# DDR32SS0_CTLPHY_WRAP_CTL_CFG_CTLCFG register map
Vendor: Texas Instruments
Registers are 32-bit, read-write, reset 0x0 unless marked. A register's access mark holds for its fields unless they carry their own. Offsets are as the file gives them; [hi:lo] are bit positions; {n}, {i} and the like mark numbered series.

## DDR32SS0_CTLPHY_WRAP_CTL_CFG_CTLCFG (part 9 of 11)
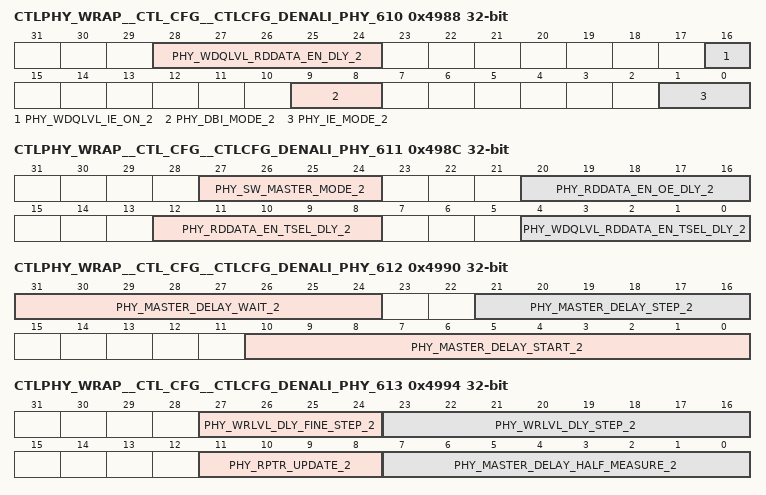
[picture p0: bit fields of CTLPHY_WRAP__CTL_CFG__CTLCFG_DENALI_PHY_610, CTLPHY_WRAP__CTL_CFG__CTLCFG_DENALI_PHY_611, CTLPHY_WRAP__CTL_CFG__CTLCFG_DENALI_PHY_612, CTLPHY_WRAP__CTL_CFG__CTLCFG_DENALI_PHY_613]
0x4988 CTLPHY_WRAP__CTL_CFG__CTLCFG_DENALI_PHY_610
  [28:24] PHY_WDQLVL_RDDATA_EN_DLY_2 — For WR DQ training, the number of cycles that the dfi_rddata_en signal is early for slice 2.
  [16] PHY_WDQLVL_IE_ON_2 — IE control, 1 meams IE is always on during WR DQ training for slice 2.
  [9:8] PHY_DBI_MODE_2 — DBI mode for slice 2. Bit [0] enables return of DBI read data.
  [1:0] PHY_IE_MODE_2 — Input enable mode bits for slice 2. Bit [0] enables the mode where the input enables are always on; set to 1 to enable. Bit [1] disables the input enable on the DM signal; set to 1 to disable.
0x498C CTLPHY_WRAP__CTL_CFG__CTLCFG_DENALI_PHY_611
  [27:24] PHY_SW_MASTER_MODE_2 — Controller delay line override settings for slice 2. Bit [0] enables software half clock mode. Bit [1] is the software half clock mode value. Bit [2] enables software bypass mode. Bit [3] is the software bypass mode value.
  [20:16] PHY_RDDATA_EN_OE_DLY_2 — Number of cycles that the dfi_rddata_en signal is earlier than necessary for LP4 OE extension generation for slice 2.
  [12:8] PHY_RDDATA_EN_TSEL_DLY_2 — Number of cycles that the dfi_rddata_en signal is earlier than necessary for TSEL enable generation for slice 2.
  [4:0] PHY_WDQLVL_RDDATA_EN_TSEL_DLY_2 — For WR DQ training, the number of cycles that the dfi_rddata_en signal is earlier than necessary for TSEL enable generation for slice 2.
0x4990 CTLPHY_WRAP__CTL_CFG__CTLCFG_DENALI_PHY_612
  [31:24] PHY_MASTER_DELAY_WAIT_2 — Wait cycles for controller delay line locking algorithm for slice 2. Bits [3:0] are the cycle wait count after a calibration clock setting change. Bits [7:4] are the cycle wait count after a controller delay setting change.
  [21:16] PHY_MASTER_DELAY_STEP_2 — Incremental step size for controller delay line locking algorithm for slice 2.
  [10:0] PHY_MASTER_DELAY_START_2 — Start value for controller delay line locking algorithm for slice 2.
0x4994 CTLPHY_WRAP__CTL_CFG__CTLCFG_DENALI_PHY_613
  [27:24] PHY_WRLVL_DLY_FINE_STEP_2 — DQS target delay fine step size during write leveling for slice 2.
  [23:16] PHY_WRLVL_DLY_STEP_2 — DQS target delay step size during write leveling for slice 2.
  [11:8] PHY_RPTR_UPDATE_2 — Offset in cycles from the dfi_rddata_en signal to release data from the entry FIFO for slice 2.
  [7:0] PHY_MASTER_DELAY_HALF_MEASURE_2 — Defines the number of delay line elements to be considered in determing whether to lock to a half clock cycle in the data slice controller for slice 2.
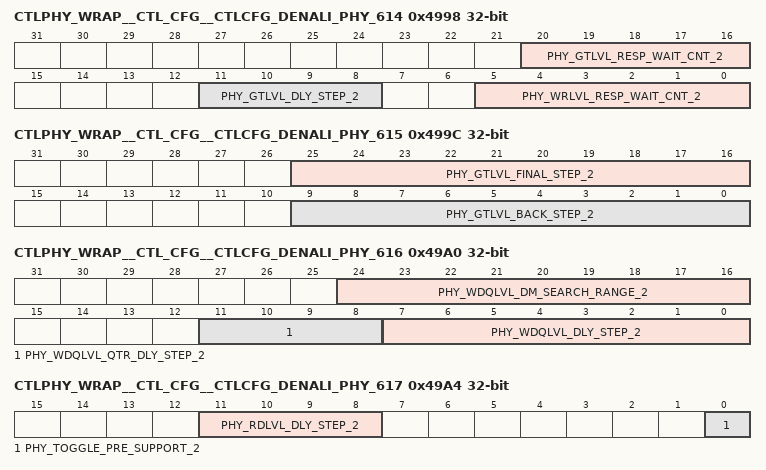
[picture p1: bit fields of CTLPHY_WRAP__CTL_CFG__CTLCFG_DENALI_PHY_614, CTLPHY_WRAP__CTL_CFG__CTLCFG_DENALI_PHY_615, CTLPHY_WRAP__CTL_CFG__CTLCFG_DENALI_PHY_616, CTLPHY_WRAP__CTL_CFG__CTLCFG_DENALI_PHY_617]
0x4998 CTLPHY_WRAP__CTL_CFG__CTLCFG_DENALI_PHY_614
  [20:16] PHY_GTLVL_RESP_WAIT_CNT_2 — Number of cycles + 4 to wait between dfi_rddata_en and the sampling of the DQS during gate training for slice 2. The valid range is 0x0 to 0xB.
  [11:8] PHY_GTLVL_DLY_STEP_2 — DQS target delay step size during gate training for slice 2.
  [5:0] PHY_WRLVL_RESP_WAIT_CNT_2 — Number of cycles to wait between dfi_wrlvl_strobe and the sampling of the DQs during write leveling for slice 2.
0x499C CTLPHY_WRAP__CTL_CFG__CTLCFG_DENALI_PHY_615
  [25:16] PHY_GTLVL_FINAL_STEP_2 — Final backup step delay used in gate training algorithm for slice 2.
  [9:0] PHY_GTLVL_BACK_STEP_2 — Interim backup step delay used in gate training algorithm for slice 2.
0x49A0 CTLPHY_WRAP__CTL_CFG__CTLCFG_DENALI_PHY_616
  [24:16] PHY_WDQLVL_DM_SEARCH_RANGE_2 — The dm target delay search range for non-lpddr4 DM training for slice 2.
  [11:8] PHY_WDQLVL_QTR_DLY_STEP_2 — Defines the step granularity for the logic to use once an edge is found for slice 2. When this occurs, the logic jumps back to the previous invalid value and uses this step size to determine a more accurate delay value.
  [7:0] PHY_WDQLVL_DLY_STEP_2 — DQ target delay step size during write data leveling for slice 2.
0x49A4 CTLPHY_WRAP__CTL_CFG__CTLCFG_DENALI_PHY_617
  [11:8] PHY_RDLVL_DLY_STEP_2 — DQS target delay step size during read leveling for slice 2.
  [0] PHY_TOGGLE_PRE_SUPPORT_2 — Support the toggle read preamble for LPDDR4 for slice 2.
0x49A8 CTLPHY_WRAP__CTL_CFG__CTLCFG_DENALI_PHY_618
  [9:0] PHY_RDLVL_MAX_EDGE_2 — The maximun rdlvl target delay search window for read eye training for slice 2.
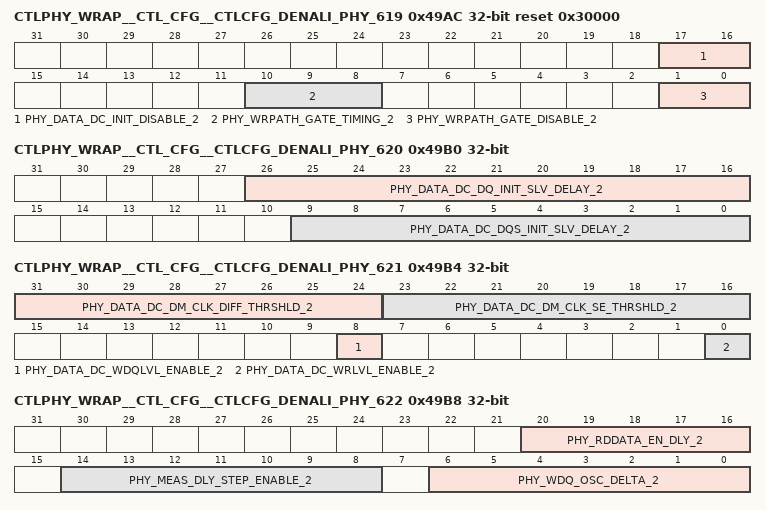
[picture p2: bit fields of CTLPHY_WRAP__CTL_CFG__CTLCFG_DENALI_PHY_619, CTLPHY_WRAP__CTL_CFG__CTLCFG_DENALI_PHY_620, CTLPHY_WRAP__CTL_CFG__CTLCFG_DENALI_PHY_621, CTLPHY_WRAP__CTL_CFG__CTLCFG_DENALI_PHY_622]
0x49AC CTLPHY_WRAP__CTL_CFG__CTLCFG_DENALI_PHY_619 reset 0x30000
  [17:16] PHY_DATA_DC_INIT_DISABLE_2 — Disable duty cycle adjust at initialization for slice 2.
  [10:8] PHY_WRPATH_GATE_TIMING_2 — Write path clock gating timing for slice 2. it means additional clock number to write path clock gate
  [1:0] PHY_WRPATH_GATE_DISABLE_2 — Write path clock gating disable for slice 2. [0]: disable pull in wrdata_en; [1]: disable write path clock gating, clock always on
0x49B0 CTLPHY_WRAP__CTL_CFG__CTLCFG_DENALI_PHY_620
  [26:16] PHY_DATA_DC_DQ_INIT_SLV_DELAY_2 — Initial value of write DQ target delay for slice 2.
  [9:0] PHY_DATA_DC_DQS_INIT_SLV_DELAY_2 — Initial value of write DQS target delay for slice 2.
0x49B4 CTLPHY_WRAP__CTL_CFG__CTLCFG_DENALI_PHY_621
  [31:24] PHY_DATA_DC_DM_CLK_DIFF_THRSHLD_2 — Clock measurement cell threshold offset for differential signals for slice 2.
  [23:16] PHY_DATA_DC_DM_CLK_SE_THRSHLD_2 — Clock measurement cell threshold offset for single ended signals for slice 2.
  [8] PHY_DATA_DC_WDQLVL_ENABLE_2 — Enable duty cycle adjust during write DQ training for slice 2.
  [0] PHY_DATA_DC_WRLVL_ENABLE_2 — Enable duty cycle adjust during write leveling for slice 2.
0x49B8 CTLPHY_WRAP__CTL_CFG__CTLCFG_DENALI_PHY_622
  [20:16] PHY_RDDATA_EN_DLY_2 — Number of cycles that the dfi_rddata_en signal is early for slice 2.
  [14:8] PHY_MEAS_DLY_STEP_ENABLE_2 — Data slice training step definition using phy_meas_dly_step_value for slice 2.
  [6:0] PHY_WDQ_OSC_DELTA_2 — Target delay offset that applies to a 1 bit change of dfi_wdq_osc_code for slice 2.
0x49BC CTLPHY_WRAP__CTL_CFG__CTLCFG_DENALI_PHY_623
  [31:0] PHY_DQ_DM_SWIZZLE0_2 — DQ/DM bit swizzling 0 for slice 2. Bits [3:0] inform the PHY which bit in {DM,DQ]} map to DQ0, Bits [7:4] inform the PHY which bit in {DM,DQ} map to DQ1, etc.
0x49C0 CTLPHY_WRAP__CTL_CFG__CTLCFG_DENALI_PHY_624
  [3:0] PHY_DQ_DM_SWIZZLE1_2 — DQ/DM bit swizzling 1 for slice 2. Bits [3:0] inform the PHY which bit in {DM,DQ]} map to DM.
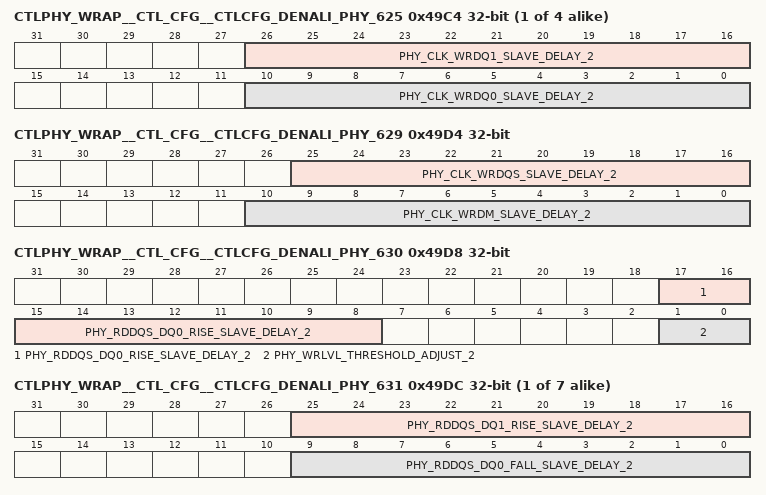
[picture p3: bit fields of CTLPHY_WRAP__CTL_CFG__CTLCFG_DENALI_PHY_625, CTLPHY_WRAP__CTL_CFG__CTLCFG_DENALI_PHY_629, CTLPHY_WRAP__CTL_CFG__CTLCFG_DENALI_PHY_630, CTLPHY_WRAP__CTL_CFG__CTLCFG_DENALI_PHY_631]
{0x4000+4i} CTLPHY_WRAP__CTL_CFG__CTLCFG_DENALI_PHY_{i} (i=625..628)
  [26:16] PHY_CLK_WRDQ{2i-1249}_SLAVE_DELAY_2 — Write clock target delay setting for DQ{2i-1249} for slice 2.
  [10:0] PHY_CLK_WRDQ{2i-1250}_SLAVE_DELAY_2 — Write clock target delay setting for DQ{2i-1250} for slice 2.
0x49D4 CTLPHY_WRAP__CTL_CFG__CTLCFG_DENALI_PHY_629
  [25:16] PHY_CLK_WRDQS_SLAVE_DELAY_2 — Write clock target delay setting for DQS for slice 2.
  [10:0] PHY_CLK_WRDM_SLAVE_DELAY_2 — Write clock target delay setting for DM for slice 2.
0x49D8 CTLPHY_WRAP__CTL_CFG__CTLCFG_DENALI_PHY_630
  [17:8] PHY_RDDQS_DQ0_RISE_SLAVE_DELAY_2 — Rising edge read DQS target delay setting for DQ0 for slice 2.
  [1:0] PHY_WRLVL_THRESHOLD_ADJUST_2 — Write level threshold adjust value based on those thresholds for DQS for slice 2.
{0x4000+4i} CTLPHY_WRAP__CTL_CFG__CTLCFG_DENALI_PHY_{i} (i=631..637)
  [25:16] PHY_RDDQS_DQ{i-630}_RISE_SLAVE_DELAY_2 — Rising edge read DQS target delay setting for DQ{i-630} for slice 2.
  [9:0] PHY_RDDQS_DQ{i-631}_FALL_SLAVE_DELAY_2 — Falling edge read DQS target delay setting for DQ{i-631} for slice 2.
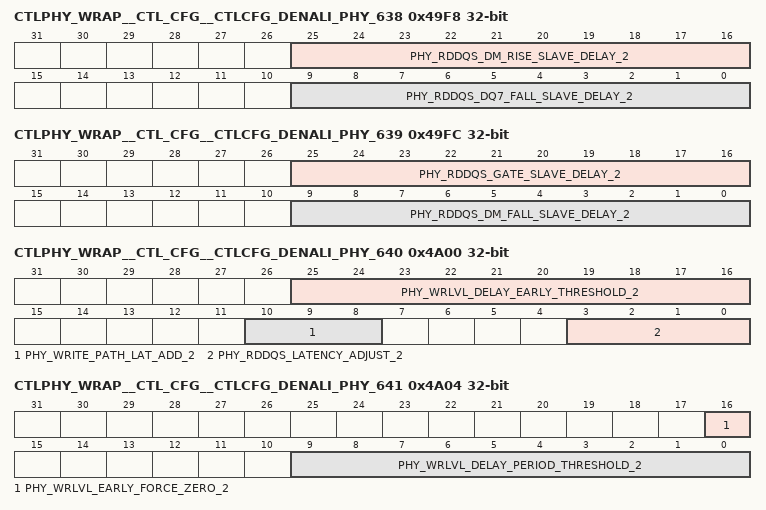
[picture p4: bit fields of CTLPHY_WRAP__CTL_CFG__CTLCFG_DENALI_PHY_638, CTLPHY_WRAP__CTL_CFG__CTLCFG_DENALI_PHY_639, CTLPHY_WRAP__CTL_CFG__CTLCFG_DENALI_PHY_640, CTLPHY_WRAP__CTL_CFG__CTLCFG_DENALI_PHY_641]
0x49F8 CTLPHY_WRAP__CTL_CFG__CTLCFG_DENALI_PHY_638
  [25:16] PHY_RDDQS_DM_RISE_SLAVE_DELAY_2 — Rising edge read DQS target delay setting for DM for slice 2.
  [9:0] PHY_RDDQS_DQ7_FALL_SLAVE_DELAY_2 — Falling edge read DQS target delay setting for DQ7 for slice 2.
0x49FC CTLPHY_WRAP__CTL_CFG__CTLCFG_DENALI_PHY_639
  [25:16] PHY_RDDQS_GATE_SLAVE_DELAY_2 — Read DQS target delay setting for slice 2.
  [9:0] PHY_RDDQS_DM_FALL_SLAVE_DELAY_2 — Falling edge read DQS target delay setting for DM for slice 2.
0x4A00 CTLPHY_WRAP__CTL_CFG__CTLCFG_DENALI_PHY_640
  [25:16] PHY_WRLVL_DELAY_EARLY_THRESHOLD_2 — Write level delay threshold above which will be considered in previous cycle for slice 2.
  [10:8] PHY_WRITE_PATH_LAT_ADD_2 — Number of cycles to delay the incoming dfi_wrdata_en/dfi_wrdata signals for slice 2.
  [3:0] PHY_RDDQS_LATENCY_ADJUST_2 — Number of cycles to delay the incoming dfi_rddata_en for read DQS gate generation for slice 2.
0x4A04 CTLPHY_WRAP__CTL_CFG__CTLCFG_DENALI_PHY_641
  [16] PHY_WRLVL_EARLY_FORCE_ZERO_2 — Force the final write level delay value [that meets the early threshold] to 0 for slice 2.
  [9:0] PHY_WRLVL_DELAY_PERIOD_THRESHOLD_2 — Write level delay threshold below which will add a cycle of write path latency for slice 2.
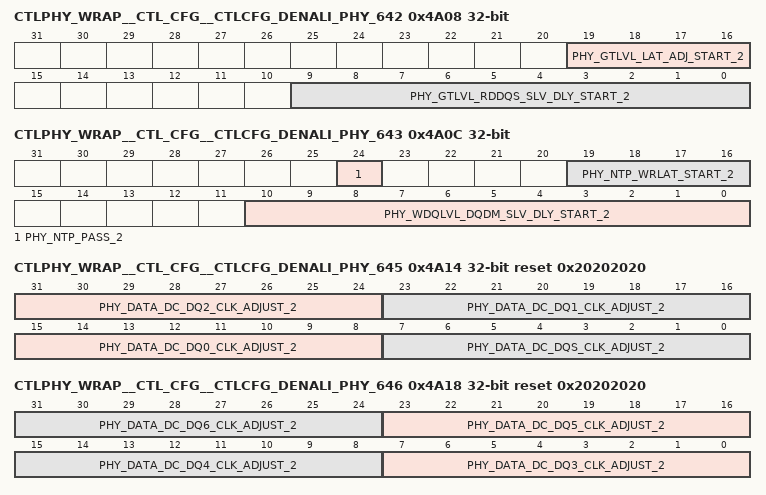
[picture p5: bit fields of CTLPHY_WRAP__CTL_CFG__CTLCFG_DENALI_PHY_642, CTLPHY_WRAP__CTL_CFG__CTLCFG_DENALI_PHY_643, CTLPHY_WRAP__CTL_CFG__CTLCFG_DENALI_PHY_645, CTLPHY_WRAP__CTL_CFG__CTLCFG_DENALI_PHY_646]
0x4A08 CTLPHY_WRAP__CTL_CFG__CTLCFG_DENALI_PHY_642
  [19:16] PHY_GTLVL_LAT_ADJ_START_2 — Initial read DQS gate cycle delay from dfi_rddata_en during gate training for slice 2.
  [9:0] PHY_GTLVL_RDDQS_SLV_DLY_START_2 — Initial read DQS gate target delay setting during gate training for slice 2.
0x4A0C CTLPHY_WRAP__CTL_CFG__CTLCFG_DENALI_PHY_643
  [24] PHY_NTP_PASS_2 — Indicates if No-topology training found a passing result for slice 2.
  [19:16] PHY_NTP_WRLAT_START_2 — Initial value for phy_write_path_lat_add for No-topology training and early threshold for slice 2.
  [10:0] PHY_WDQLVL_DQDM_SLV_DLY_START_2 — Initial DQ/DM target delay setting during write data leveling for slice 2.
0x4A10 CTLPHY_WRAP__CTL_CFG__CTLCFG_DENALI_PHY_644
  [9:0] PHY_RDLVL_RDDQS_DQ_SLV_DLY_START_2 — Read leveling starting value for the DQS/DQ target delay settings for slice 2.
0x4A14 CTLPHY_WRAP__CTL_CFG__CTLCFG_DENALI_PHY_645 reset 0x20202020
  [31:24] PHY_DATA_DC_DQ2_CLK_ADJUST_2 — Adjust value of Duty Cycle Adjuster for slice 2.
  [23:16] PHY_DATA_DC_DQ1_CLK_ADJUST_2 — Adjust value of Duty Cycle Adjuster for slice 2.
  [15:8] PHY_DATA_DC_DQ0_CLK_ADJUST_2 — Adjust value of Duty Cycle Adjuster for slice 2.
  [7:0] PHY_DATA_DC_DQS_CLK_ADJUST_2 — Adjust value of Duty Cycle Adjuster for slice 2.
0x4A18 CTLPHY_WRAP__CTL_CFG__CTLCFG_DENALI_PHY_646 reset 0x20202020
  [8n-17:8n-24] PHY_DATA_DC_DQ{n}_CLK_ADJUST_2 (n=3..6) — Adjust value of Duty Cycle Adjuster for slice 2.
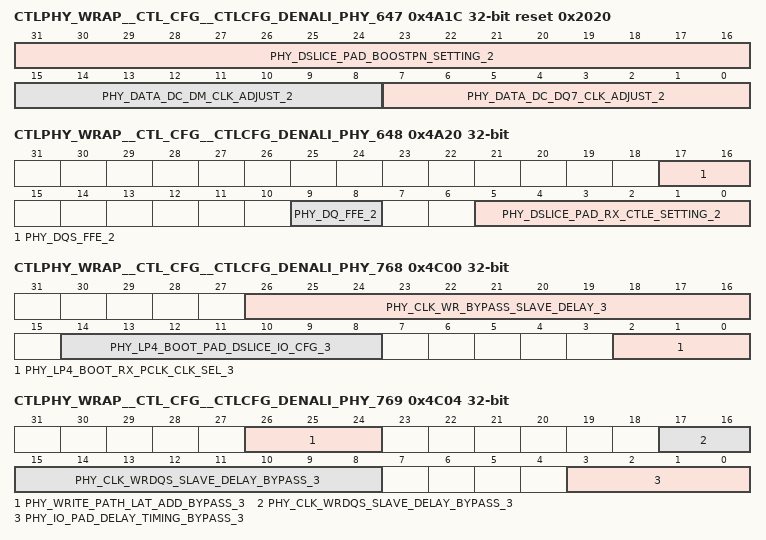
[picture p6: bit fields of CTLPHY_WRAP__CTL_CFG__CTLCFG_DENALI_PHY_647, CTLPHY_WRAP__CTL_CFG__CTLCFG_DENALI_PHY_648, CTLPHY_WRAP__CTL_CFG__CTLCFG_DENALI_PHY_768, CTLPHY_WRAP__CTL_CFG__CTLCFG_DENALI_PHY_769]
0x4A1C CTLPHY_WRAP__CTL_CFG__CTLCFG_DENALI_PHY_647 reset 0x2020
  [31:16] PHY_DSLICE_PAD_BOOSTPN_SETTING_2 — Setting for boost P/N of pad for slice 2.
  [15:8] PHY_DATA_DC_DM_CLK_ADJUST_2 — Adjust value of Duty Cycle Adjuster for slice 2.
  [7:0] PHY_DATA_DC_DQ7_CLK_ADJUST_2 — Adjust value of Duty Cycle Adjuster for slice 2.
0x4A20 CTLPHY_WRAP__CTL_CFG__CTLCFG_DENALI_PHY_648
  [17:16] PHY_DQS_FFE_2 — TX_FFE setting for DQS pad for slice 2.
  [9:8] PHY_DQ_FFE_2 — TX_FFE setting for DQ/DM pad for slice 2.
  [5:0] PHY_DSLICE_PAD_RX_CTLE_SETTING_2 — Setting for RX ctle P/N of pad for slice 2.
0x4C00 CTLPHY_WRAP__CTL_CFG__CTLCFG_DENALI_PHY_768
  [26:16] PHY_CLK_WR_BYPASS_SLAVE_DELAY_3 — Write data clock bypass mode target delay setting for slice 3.
  [14:8] PHY_LP4_BOOT_PAD_DSLICE_IO_CFG_3 — Controls PCLK/PARK pin for pad for slice 3 with boot frequency.
  [2:0] PHY_LP4_BOOT_RX_PCLK_CLK_SEL_3 — RX_PCLK boot clock frequency selection for slice 3.
0x4C04 CTLPHY_WRAP__CTL_CFG__CTLCFG_DENALI_PHY_769
  [26:24] PHY_WRITE_PATH_LAT_ADD_BYPASS_3 — Number of cycles on bypass mode to delay the incoming dfi_wrdata_en/dfi_wrdata signals for slice 3.
  [17:8] PHY_CLK_WRDQS_SLAVE_DELAY_BYPASS_3 — Write DQS bypass mode target delay setting for slice 3.
  [3:0] PHY_IO_PAD_DELAY_TIMING_BYPASS_3 — Feedback pad's OPAD and IPAD delay timing on bypass mode for slice 3.
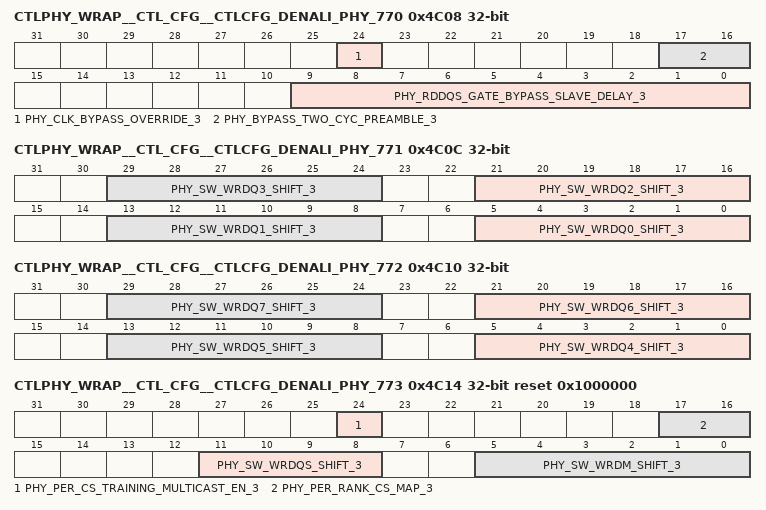
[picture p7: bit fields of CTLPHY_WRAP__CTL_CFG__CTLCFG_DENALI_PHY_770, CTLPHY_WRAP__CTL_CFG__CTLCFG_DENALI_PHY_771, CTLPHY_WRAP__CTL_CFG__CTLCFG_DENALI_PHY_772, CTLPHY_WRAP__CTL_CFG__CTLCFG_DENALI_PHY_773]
0x4C08 CTLPHY_WRAP__CTL_CFG__CTLCFG_DENALI_PHY_770
  [24] PHY_CLK_BYPASS_OVERRIDE_3 — Bypass mode override setting for slice 3.
  [17:16] PHY_BYPASS_TWO_CYC_PREAMBLE_3 — Two_cycle_preamble for bypass mode for slice 3.
  [9:0] PHY_RDDQS_GATE_BYPASS_SLAVE_DELAY_3 — Read DQS bypass mode target delay setting for slice 3.
0x4C0C CTLPHY_WRAP__CTL_CFG__CTLCFG_DENALI_PHY_771
  [8n+5:8n] PHY_SW_WRDQ{n}_SHIFT_3 (n=0..3) — Manual override of automatic half_cycle_shift/cycle_shift for write DQ{n} for slice 3. Bit [0] enables override of half_cycle_shift. Bit [1] is the half_cycle_shift value. Bit [2] enables override of cycle shift. Bits [4:3] are the cycle_shift value.
0x4C10 CTLPHY_WRAP__CTL_CFG__CTLCFG_DENALI_PHY_772
  [8n-27:8n-32] PHY_SW_WRDQ{n}_SHIFT_3 (n=4..7) — Manual override of automatic half_cycle_shift/cycle_shift for write DQ{n} for slice 3. Bit [0] enables override of half_cycle_shift. Bit [1] is the half_cycle_shift value. Bit [2] enables override of cycle shift. Bits [4:3] are the cycle_shift value.
0x4C14 CTLPHY_WRAP__CTL_CFG__CTLCFG_DENALI_PHY_773 reset 0x1000000
  [24] PHY_PER_CS_TRAINING_MULTICAST_EN_3 — When set, a register write will update parameters for all ranks at the same time in slice 3. Set to 1 to enable.
  [17:16] PHY_PER_RANK_CS_MAP_3 — Per-rank CS map for slice 3. Setting a bit uses that CS for the rank, bit [0] uses CS0, bit [1] uses CS1, etc.
  [11:8] PHY_SW_WRDQS_SHIFT_3 — Manual override of automatic half_cycle_shift/cycle_shift for write DQS for slice 3. Bit [0] enables override of half_cycle_shift. Bit [1] is the half_cycle_shift value. Bit [2] enables override of cycle shift. Bit [3] is the cycle_shift value.
  [5:0] PHY_SW_WRDM_SHIFT_3 — Manual override of automatic half_cycle_shift/cycle_shift for write DM for slice 3. Bit [0] enables override of half_cycle_shift. Bit [1] is the half_cycle_shift value. Bit [2] enables override of cycle shift. Bits [4:3] are the cycle_shift value.
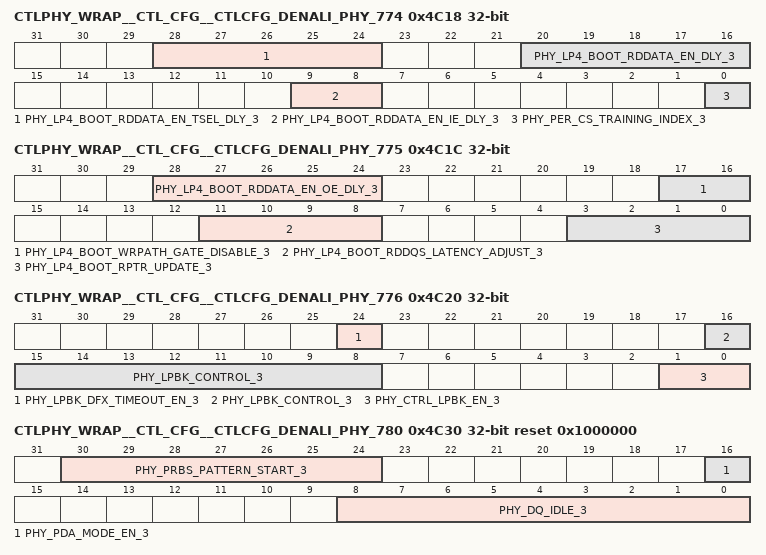
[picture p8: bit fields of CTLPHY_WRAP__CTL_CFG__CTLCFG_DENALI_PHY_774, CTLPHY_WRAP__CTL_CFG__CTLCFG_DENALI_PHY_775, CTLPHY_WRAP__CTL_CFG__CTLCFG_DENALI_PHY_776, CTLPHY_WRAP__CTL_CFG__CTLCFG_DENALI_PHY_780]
0x4C18 CTLPHY_WRAP__CTL_CFG__CTLCFG_DENALI_PHY_774
  [28:24] PHY_LP4_BOOT_RDDATA_EN_TSEL_DLY_3 — For LPDDR4 boot frequency, the number of cycles that the dfi_rddata_en signal is earlier than necessary for TSEL enable generation for slice 3.
  [20:16] PHY_LP4_BOOT_RDDATA_EN_DLY_3 — For LPDDR4 boot frequency, the number of cycles that the dfi_rddata_en signal is early for slice 3.
  [9:8] PHY_LP4_BOOT_RDDATA_EN_IE_DLY_3 — For LPDDR4 boot frequency, the number of cycles that the dfi_rddata_en signal is earlier than necessary for input enable generation for slice 3.
  [0] PHY_PER_CS_TRAINING_INDEX_3 — For per-rank training, indicates which rank's paramters are read/written for slice 3.
0x4C1C CTLPHY_WRAP__CTL_CFG__CTLCFG_DENALI_PHY_775
  [28:24] PHY_LP4_BOOT_RDDATA_EN_OE_DLY_3 — For LPDDR4 boot frequency, the number of cycles that the dfi_rddata_en signal is earlier than necessary for extended OE generation for slice 3.
  [17:16] PHY_LP4_BOOT_WRPATH_GATE_DISABLE_3 — For LPDDR4 boot frequency, write path clock gating disable for slice 3. Bit [0]: disable pull in wrdata_en; Bit [1]: disable write path clock gating, clock always on
  [11:8] PHY_LP4_BOOT_RDDQS_LATENCY_ADJUST_3 — For LPDDR4 boot frequency, the number of cycles to delay the incoming dfi_rddata_en for read DQS gate generation for slice 3.
  [3:0] PHY_LP4_BOOT_RPTR_UPDATE_3 — For LPDDR4 boot frequency, the offset in cycles from the dfi_rddata_en signal to releasing data from the entry FIFO for slice 3.
0x4C20 CTLPHY_WRAP__CTL_CFG__CTLCFG_DENALI_PHY_776
  [24] PHY_LPBK_DFX_TIMEOUT_EN_3 — Loopback read only test timeout mechanism enable for slice 3.
  [16:8] PHY_LPBK_CONTROL_3 — Loopback control bits for slice 3.
  [1:0] PHY_CTRL_LPBK_EN_3 — Loopback control en for slice 3.
0x4C24 CTLPHY_WRAP__CTL_CFG__CTLCFG_DENALI_PHY_777
  [0] PHY_GATE_DELAY_COMP_DISABLE_3 — use the control whether to compensate half_cycle when gate_target_delay is larger than half_cycle for the gate close for slice 3.
0x4C28 CTLPHY_WRAP__CTL_CFG__CTLCFG_DENALI_PHY_778
  [31:0] PHY_AUTO_TIMING_MARGIN_CONTROL_3 — Auto timing marging control bits for slice 3.
0x4C2C CTLPHY_WRAP__CTL_CFG__CTLCFG_DENALI_PHY_779 ro
  [27:0] PHY_AUTO_TIMING_MARGIN_OBS_3 — Observation register for the auto_timing_margin for slice 3. READ-ONLY
0x4C30 CTLPHY_WRAP__CTL_CFG__CTLCFG_DENALI_PHY_780 reset 0x1000000
  [30:24] PHY_PRBS_PATTERN_START_3 — PRBS7 start pattern for slice 3.
  [16] PHY_PDA_MODE_EN_3 — When set to 1, the invalid DQs will be driven by the dfi_wrdata to make sure the tpda_s and tpda_h's timing is meet for slice 3.
  [8:0] PHY_DQ_IDLE_3 — When set to 1, the inavlid DQ will be driven to high, when set to 0, the invalid DQ will be driven to low for slice 3.
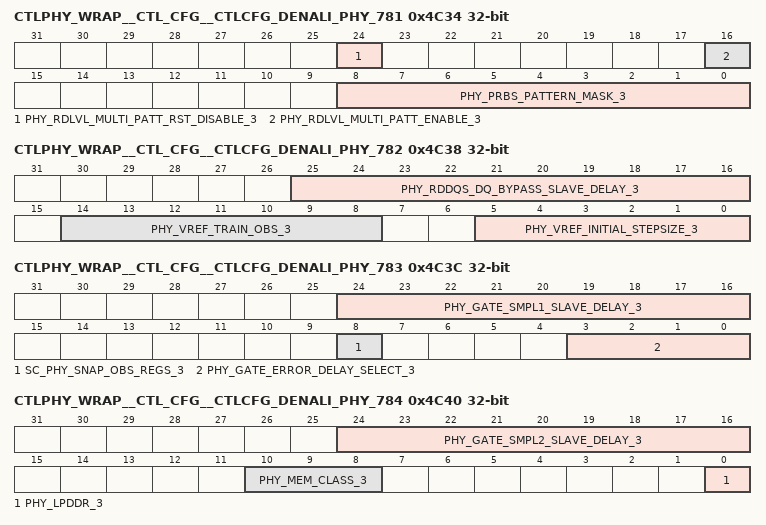
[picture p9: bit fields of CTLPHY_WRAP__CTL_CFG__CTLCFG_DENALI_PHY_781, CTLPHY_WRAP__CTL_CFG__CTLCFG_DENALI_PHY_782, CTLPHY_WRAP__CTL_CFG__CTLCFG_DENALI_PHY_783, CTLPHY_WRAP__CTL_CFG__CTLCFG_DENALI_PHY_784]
0x4C34 CTLPHY_WRAP__CTL_CFG__CTLCFG_DENALI_PHY_781
  [24] PHY_RDLVL_MULTI_PATT_RST_DISABLE_3 — Read Leveling read level windows disable reset for slice 3.
  [16] PHY_RDLVL_MULTI_PATT_ENABLE_3 — Read Leveling Multi-pattern enable for slice 3.
  [8:0] PHY_PRBS_PATTERN_MASK_3 — PRBS7 mask signal for slice 3.
0x4C38 CTLPHY_WRAP__CTL_CFG__CTLCFG_DENALI_PHY_782 access per field
  [25:16] PHY_RDDQS_DQ_BYPASS_SLAVE_DELAY_3 rw — Read DQS data clock bypass mode target delay setting for slice 3.
  [14:8] PHY_VREF_TRAIN_OBS_3 ro — Observation register for best vref value for slice 3. READ-ONLY
  [5:0] PHY_VREF_INITIAL_STEPSIZE_3 rw — Data slice initial VREF training step size for slice 3.
0x4C3C CTLPHY_WRAP__CTL_CFG__CTLCFG_DENALI_PHY_783 access per field
  [24:16] PHY_GATE_SMPL1_SLAVE_DELAY_3 rw — Number of cycles to delay the read DQS gate signal to generate gate1 signal for on-the-fly read DQS training for slice 3.
  [8] SC_PHY_SNAP_OBS_REGS_3 wo — Initiates a snapshot of the internal observation registers for slice 3. Set to 1 to trigger. WRITE-ONLY
  [3:0] PHY_GATE_ERROR_DELAY_SELECT_3 rw — Number of cycles to wait for the DQS gate to close before flagging an error for slice 3.
0x4C40 CTLPHY_WRAP__CTL_CFG__CTLCFG_DENALI_PHY_784
  [24:16] PHY_GATE_SMPL2_SLAVE_DELAY_3 — Number of cycles to delay the read DQS gate signal to generate gate2 signal for on-the-fly read DQS training for slice 3.
  [10:8] PHY_MEM_CLASS_3 — Indicates the type of DRAM for slice 3. 0 for DDR3, 1 for DDR4, 2 for DDR5, 4 for LPDDR2, 5 for LPDDR3. 6 for LPDDR4
  [0] PHY_LPDDR_3 — Adds a cycle of delay for the slice 3 to match the address slice. Set to 1 to add a cycle
0x4C44 CTLPHY_WRAP__CTL_CFG__CTLCFG_DENALI_PHY_785
  [1:0] ON_FLY_GATE_ADJUST_EN_3 — Control the on-the-fly gate adjustment for slice 3.
0x4C48 CTLPHY_WRAP__CTL_CFG__CTLCFG_DENALI_PHY_786 ro
  [31:0] PHY_GATE_TRACKING_OBS_3 — Report the on-the-fly gate measurement result for slice 3. READ-ONLY
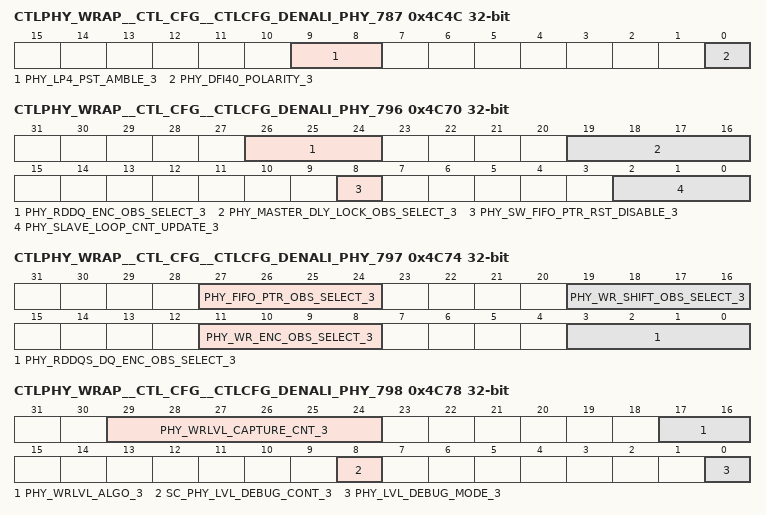
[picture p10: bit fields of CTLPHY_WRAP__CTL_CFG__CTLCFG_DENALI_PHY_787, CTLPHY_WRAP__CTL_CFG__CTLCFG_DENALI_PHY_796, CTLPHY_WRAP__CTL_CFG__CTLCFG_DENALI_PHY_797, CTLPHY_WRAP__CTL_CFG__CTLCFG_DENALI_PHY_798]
0x4C4C CTLPHY_WRAP__CTL_CFG__CTLCFG_DENALI_PHY_787
  [9:8] PHY_LP4_PST_AMBLE_3 — Controls the read postamble extension for LPDDR4 for slice 3.
  [0] PHY_DFI40_POLARITY_3 — Indicates the dfi_wrdata_cs_n and dfi_rddata_cs_n is low active or high active for slice 3.
{0x4000+4i} CTLPHY_WRAP__CTL_CFG__CTLCFG_DENALI_PHY_{i} (i=788..795)
  [31:0] PHY_RDLVL_PATT{i-780}_3 — Read leveling pattern {i-780} data for slice 3.
0x4C70 CTLPHY_WRAP__CTL_CFG__CTLCFG_DENALI_PHY_796
  [26:24] PHY_RDDQ_ENC_OBS_SELECT_3 — Select value to map the internal read DQ target delay encoded settings to the accessible read DQ encoded target delay observation register for slice 3.
  [19:16] PHY_MASTER_DLY_LOCK_OBS_SELECT_3 — Select value to map the internal controller delay observation registers to the accessible controller delay observation register for slice 3.
  [8] PHY_SW_FIFO_PTR_RST_DISABLE_3 — Disables automatic reset of the read entry FIFO pointers for slice 3. Set to 1 to disable automatic resets.
  [2:0] PHY_SLAVE_LOOP_CNT_UPDATE_3 — Reserved for future use for slice 3.
0x4C74 CTLPHY_WRAP__CTL_CFG__CTLCFG_DENALI_PHY_797
  [27:24] PHY_FIFO_PTR_OBS_SELECT_3 — Select value to map the internal read entry FIFO read/write pointers to the accessible read entry FIFO pointer observation register for slice 3.
  [19:16] PHY_WR_SHIFT_OBS_SELECT_3 — Select value to map the internal write DQ/DQS automatic cycle/half_cycle shift settings to the accessible write DQ/DQS shift observation register for slice 3.
  [11:8] PHY_WR_ENC_OBS_SELECT_3 — Select value to map the internal write DQ target delay encoded settings to the accessible write DQ encoded target delay observation register for slice 3.
  [3:0] PHY_RDDQS_DQ_ENC_OBS_SELECT_3 — Select value to map the internal read DQS DQ rise/fall target delay encoded settings to the accessible read DQS DQ rise/fall encoded target delay observation registers for slice 3.
0x4C78 CTLPHY_WRAP__CTL_CFG__CTLCFG_DENALI_PHY_798 access per field
  [29:24] PHY_WRLVL_CAPTURE_CNT_3 rw — Number of samples to take at each DQS target delay setting during write leveling for slice 3.
  [17:16] PHY_WRLVL_ALGO_3 rw — Write leveling algorithm selection for slice 3.
  [8] SC_PHY_LVL_DEBUG_CONT_3 wo — Allows the leveling state machine to advance [when in debug mode] for slice 3. Set to 1 to trigger. WRITE-ONLY
  [0] PHY_LVL_DEBUG_MODE_3 rw — Enables leveling debug mode for slice 3. Set to 1 to enable.
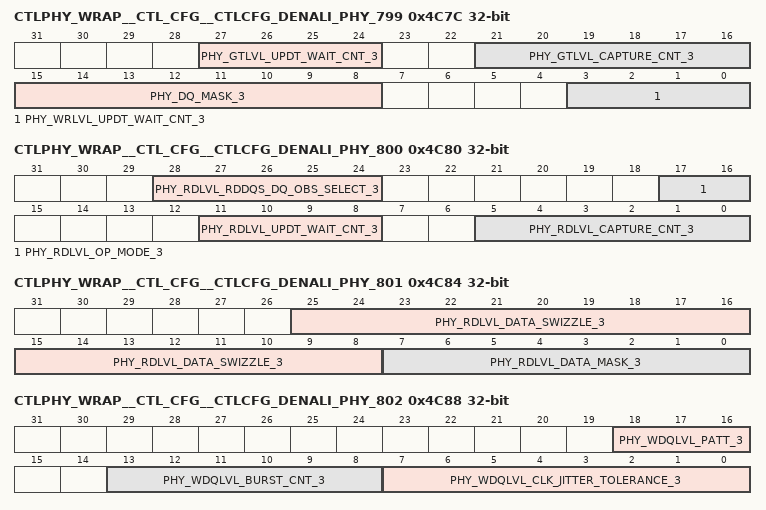
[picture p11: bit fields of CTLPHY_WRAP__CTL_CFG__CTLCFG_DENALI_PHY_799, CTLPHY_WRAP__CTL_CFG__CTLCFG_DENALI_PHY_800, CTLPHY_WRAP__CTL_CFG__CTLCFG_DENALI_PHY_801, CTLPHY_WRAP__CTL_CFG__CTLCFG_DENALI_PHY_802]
0x4C7C CTLPHY_WRAP__CTL_CFG__CTLCFG_DENALI_PHY_799
  [27:24] PHY_GTLVL_UPDT_WAIT_CNT_3 — Number of cycles + 4 to wait after changing DQS target delay setting during gate training for slice 3. The valid range is 0x0 to 0xB.
  [21:16] PHY_GTLVL_CAPTURE_CNT_3 — Number of samples to take at each DQS target delay setting during gate training for slice 3.
  [15:8] PHY_DQ_MASK_3 — For ECC slice, should set this register to do DQ bit mask for slice 3.
  [3:0] PHY_WRLVL_UPDT_WAIT_CNT_3 — Number of cycles to wait after changing DQS target delay setting during write leveling for slice 3.
0x4C80 CTLPHY_WRAP__CTL_CFG__CTLCFG_DENALI_PHY_800
  [28:24] PHY_RDLVL_RDDQS_DQ_OBS_SELECT_3 — Select value to map an individual DQ data window leading/trailing edge to the leading/trailing edge observation registers during read leveling for slice 3.
  [17:16] PHY_RDLVL_OP_MODE_3 — Read leveling algorithm select for slice 3. Clear to 0 to move linearly from left to right. Set to 1 to start inside the window, move left and then move right.
  [11:8] PHY_RDLVL_UPDT_WAIT_CNT_3 — Number of cycles to wait after changing DQS target delay setting during read leveling for slice 3.
  [5:0] PHY_RDLVL_CAPTURE_CNT_3 — Number of samples to take at each DQS target delay setting during read leveling for slice 3.
0x4C84 CTLPHY_WRAP__CTL_CFG__CTLCFG_DENALI_PHY_801
  [25:8] PHY_RDLVL_DATA_SWIZZLE_3 — Read level bit swizzling for DDR4 operation for slice 3.
  [7:0] PHY_RDLVL_DATA_MASK_3 — Per-bit mask for read leveling for slice 3. If all bits are not used, only 1 bit should be cleared to 0.
0x4C88 CTLPHY_WRAP__CTL_CFG__CTLCFG_DENALI_PHY_802
  [18:16] PHY_WDQLVL_PATT_3 — Defines the training patterns to be used during the write data leveling sequence for slice 3. Bit [0] corresponds to the LFSR data training pattern. Bit [1] corresponds to the CLK data training pattern. Bit [2] corresponds to user-defined data pattern training. If multiple bits are set, the training for each of the chosen patterns will be executed and the settings that give the smallest data valid window eye will be chosen.
  [13:8] PHY_WDQLVL_BURST_CNT_3 — Defines the write/read burst length in bytes during the write data leveling sequence for slice 3.
  [7:0] PHY_WDQLVL_CLK_JITTER_TOLERANCE_3 — Defines the minimum gap requirment for the LE and TE window for slice 3.
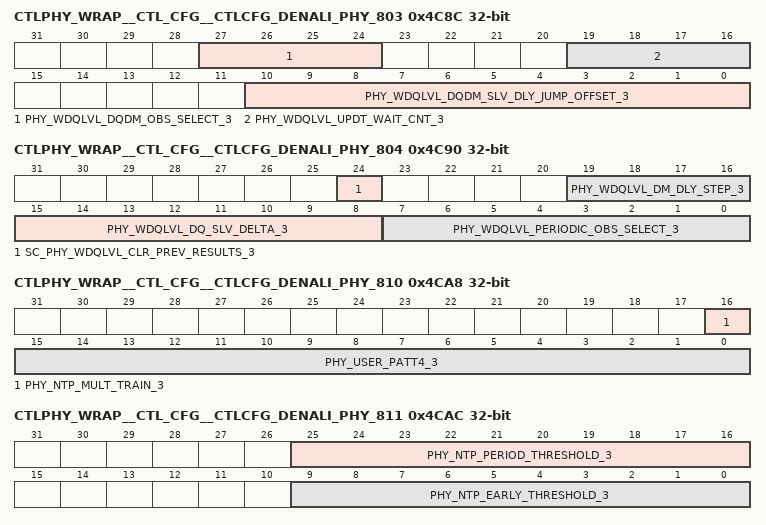
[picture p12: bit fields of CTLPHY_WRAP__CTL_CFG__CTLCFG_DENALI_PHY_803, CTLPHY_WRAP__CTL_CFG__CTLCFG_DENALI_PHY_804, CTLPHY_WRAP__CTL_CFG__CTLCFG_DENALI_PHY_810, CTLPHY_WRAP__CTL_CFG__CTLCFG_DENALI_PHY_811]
0x4C8C CTLPHY_WRAP__CTL_CFG__CTLCFG_DENALI_PHY_803
  [27:24] PHY_WDQLVL_DQDM_OBS_SELECT_3 — Select value to map an individual DQ data window leading/trailing edge to the leading/trailing edge observation registers during write data leveling for slice 3.
  [19:16] PHY_WDQLVL_UPDT_WAIT_CNT_3 — Number of cycles to wait after changing the DQ target delay setting during write data leveling for slice 3.
  [10:0] PHY_WDQLVL_DQDM_SLV_DLY_JUMP_OFFSET_3 — Defines the target delay jump value when the TE window is found and begin to serch TE window for slice 3.
0x4C90 CTLPHY_WRAP__CTL_CFG__CTLCFG_DENALI_PHY_804 access per field
  [24] SC_PHY_WDQLVL_CLR_PREV_RESULTS_3 wo — Clears the previous result value to allow a clean slate comparison for future write DQ leveling results for slice 3. Set to 1 to trigger. WRITE-ONLY
  [19:16] PHY_WDQLVL_DM_DLY_STEP_3 rw — The target delay line step for DM training for slice 3.
  [15:8] PHY_WDQLVL_DQ_SLV_DELTA_3 rw — The margin for DQ0-7's LE and TE dealy to make sure the DQ bits can work during DM training for slice 3.
  [7:0] PHY_WDQLVL_PERIODIC_OBS_SELECT_3 rw — Select value to map specific information during or post periodic write data leveling for slice 3.
0x4C94 CTLPHY_WRAP__CTL_CFG__CTLCFG_DENALI_PHY_805
  [8:0] PHY_WDQLVL_DATADM_MASK_3 — Per-bit mask for write data leveling for slice 3. Set to 1 to mask any bit from the leveling process.
{0x4000+4i} CTLPHY_WRAP__CTL_CFG__CTLCFG_DENALI_PHY_{i} (i=806..809)
  [31:0] PHY_USER_PATT{i-806}_3 — User-defined pattern to be used during write data leveling for slice 3. This register holds the bytes {4i-3221} to {4i-3224} written/read from device.
0x4CA8 CTLPHY_WRAP__CTL_CFG__CTLCFG_DENALI_PHY_810
  [16] PHY_NTP_MULT_TRAIN_3 — Control for single pass only No-Topology training for slice 3.
  [15:0] PHY_USER_PATT4_3 — User-defined pattern to be used during write data leveling for slice 3. This register holds the DM bit for the 15 to 0 DQ written/read from device.
0x4CAC CTLPHY_WRAP__CTL_CFG__CTLCFG_DENALI_PHY_811
  [25:16] PHY_NTP_PERIOD_THRESHOLD_3 — Threshold Criteria of period threshold after No-Topology training is completed for slice 3.
  [9:0] PHY_NTP_EARLY_THRESHOLD_3 — Threshold Criteria of early threshold after No-Topology training is completed for slice 3.
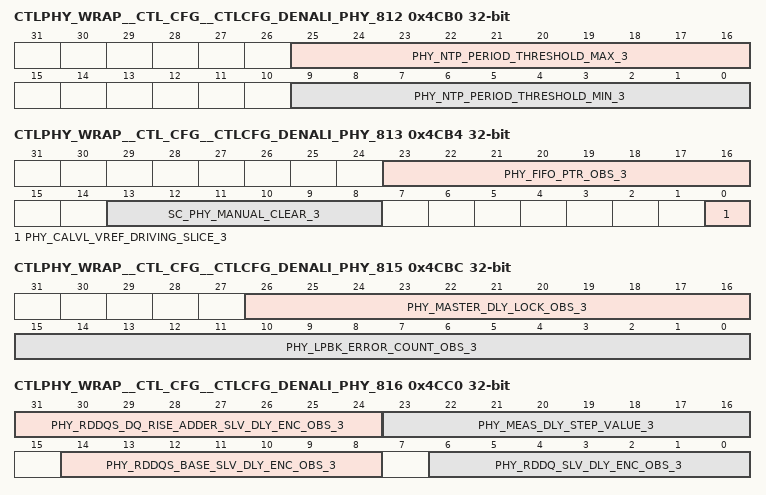
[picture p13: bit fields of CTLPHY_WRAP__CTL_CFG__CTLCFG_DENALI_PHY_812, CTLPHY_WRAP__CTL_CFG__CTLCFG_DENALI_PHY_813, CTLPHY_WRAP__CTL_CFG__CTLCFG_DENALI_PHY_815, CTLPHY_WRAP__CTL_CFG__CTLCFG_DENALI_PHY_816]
0x4CB0 CTLPHY_WRAP__CTL_CFG__CTLCFG_DENALI_PHY_812
  [25:16] PHY_NTP_PERIOD_THRESHOLD_MAX_3 — Maximum Threshold that phy_clk_wrdqs_target_delay could cross boundary, to set period threshold/early threshold after No-Topology training is completed for slice 3.
  [9:0] PHY_NTP_PERIOD_THRESHOLD_MIN_3 — Minimum Threshold that phy_clk_wrdqs_target_delay could cross boundary, to set period threshold/early threshold after No-Topology training is completed for slice 3.
0x4CB4 CTLPHY_WRAP__CTL_CFG__CTLCFG_DENALI_PHY_813 access per field
  [23:16] PHY_FIFO_PTR_OBS_3 ro — Observation register containing read entry FIFO pointers for slice 3. READ-ONLY
  [13:8] SC_PHY_MANUAL_CLEAR_3 wo — Manual reset/clear of internal logic for slice 3. Bit [0] initiates manual setup of the read DQS gate. Bit [1] is reset of read entry FIFO pointers. Bit [2] is reset of controller delay min/max lock values. Bit [3] is manual reset of controller delay unlock counter. Bit [4] is reset of leveling error bit in the leveling status registers. Bit [5] is clearing of the gate tracking observation register. Set each bit to 1 to initiate/reset. WRITE-ONLY
  [0] PHY_CALVL_VREF_DRIVING_SLICE_3 rw — Indicates if slice 3 is used to drive the VREF value to the device during CA training.
0x4CB8 CTLPHY_WRAP__CTL_CFG__CTLCFG_DENALI_PHY_814 ro reset 0x100000
  [31:0] PHY_LPBK_RESULT_OBS_3 — Observation register containing loopback status/results for slice 3. READ-ONLY
0x4CBC CTLPHY_WRAP__CTL_CFG__CTLCFG_DENALI_PHY_815 ro
  [26:16] PHY_MASTER_DLY_LOCK_OBS_3 — Observation register containing controller delay results for slice 3. READ-ONLY
  [15:0] PHY_LPBK_ERROR_COUNT_OBS_3 — Observation register containing total number of loopback error data for slice 3. READ-ONLY
0x4CC0 CTLPHY_WRAP__CTL_CFG__CTLCFG_DENALI_PHY_816 ro
  [31:24] PHY_RDDQS_DQ_RISE_ADDER_SLV_DLY_ENC_OBS_3 — Observation register containing read DQS DQ rising edge adder target delay encoded value for slice 3. READ-ONLY
  [23:16] PHY_MEAS_DLY_STEP_VALUE_3 — Observation register containing fraction of the cycle in 1 delay element, numerator with demominator of 512, for slice 3. READ-ONLY
  [14:8] PHY_RDDQS_BASE_SLV_DLY_ENC_OBS_3 — Observation register containing read DQS base target delay encoded value for slice 3. READ-ONLY
  [6:0] PHY_RDDQ_SLV_DLY_ENC_OBS_3 — Observation register containing read DQ target delay encoded values for slice 3. READ-ONLY
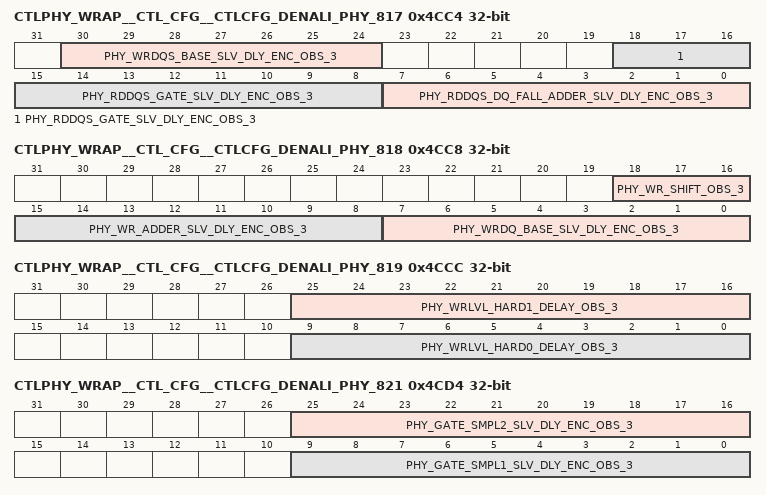
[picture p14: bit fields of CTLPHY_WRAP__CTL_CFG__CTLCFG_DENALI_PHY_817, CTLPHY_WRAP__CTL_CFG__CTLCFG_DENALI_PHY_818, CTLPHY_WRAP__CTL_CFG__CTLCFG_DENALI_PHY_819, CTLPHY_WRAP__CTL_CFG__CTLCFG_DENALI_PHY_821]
0x4CC4 CTLPHY_WRAP__CTL_CFG__CTLCFG_DENALI_PHY_817 ro
  [30:24] PHY_WRDQS_BASE_SLV_DLY_ENC_OBS_3 — Observation register containing write DQS base target delay encoded value for slice 3. READ-ONLY
  [18:8] PHY_RDDQS_GATE_SLV_DLY_ENC_OBS_3 — Observation register containing read DQS gate target delay encoded value for slice 3. READ-ONLY
  [7:0] PHY_RDDQS_DQ_FALL_ADDER_SLV_DLY_ENC_OBS_3 — Observation register containing read DQS DQ falling edge adder target delay encoded value for slice 3. READ-ONLY
0x4CC8 CTLPHY_WRAP__CTL_CFG__CTLCFG_DENALI_PHY_818 ro
  [18:16] PHY_WR_SHIFT_OBS_3 — Observation register containing automatic half cycle and cycle shift values for slice 3. READ-ONLY
  [15:8] PHY_WR_ADDER_SLV_DLY_ENC_OBS_3 — Observation register containing write adder target delay encoded value for slice 3. READ-ONLY
  [7:0] PHY_WRDQ_BASE_SLV_DLY_ENC_OBS_3 — Observation register containing write DQ base target delay encoded value for slice 3. READ-ONLY
0x4CCC CTLPHY_WRAP__CTL_CFG__CTLCFG_DENALI_PHY_819 ro
  [25:16] PHY_WRLVL_HARD1_DELAY_OBS_3 — Observation register containing write leveling first hard 1 DQS target delay for slice 3. READ-ONLY
  [9:0] PHY_WRLVL_HARD0_DELAY_OBS_3 — Observation register containing write leveling last hard 0 DQS target delay for slice 3. READ-ONLY
0x4CD0 CTLPHY_WRAP__CTL_CFG__CTLCFG_DENALI_PHY_820 ro
  [20:0] PHY_WRLVL_STATUS_OBS_3 — Observation register containing write leveling status for slice 3. READ-ONLY
0x4CD4 CTLPHY_WRAP__CTL_CFG__CTLCFG_DENALI_PHY_821 ro
  [25:16] PHY_GATE_SMPL2_SLV_DLY_ENC_OBS_3 — Observation register containing gate sample2 target delay encoded values for slice 3. READ-ONLY
  [9:0] PHY_GATE_SMPL1_SLV_DLY_ENC_OBS_3 — Observation register containing gate sample1 target delay encoded values for slice 3. READ-ONLY
0x4CD8 CTLPHY_WRAP__CTL_CFG__CTLCFG_DENALI_PHY_822 ro
  [29:16] PHY_GTLVL_HARD0_DELAY_OBS_3 — Observation register containing gate training first hard 0 DQS target delay for slice 3. READ-ONLY
  [15:0] PHY_WRLVL_ERROR_OBS_3 — Observation register containing write leveling error status for slice 3. READ-ONLY
0x4CDC CTLPHY_WRAP__CTL_CFG__CTLCFG_DENALI_PHY_823 ro
  [13:0] PHY_GTLVL_HARD1_DELAY_OBS_3 — Observation register containing gate training last hard 1 DQS target delay for slice 3. READ-ONLY
0x4CE0 CTLPHY_WRAP__CTL_CFG__CTLCFG_DENALI_PHY_824 ro
  [17:0] PHY_GTLVL_STATUS_OBS_3 — Observation register containing gate training status for slice 3. READ-ONLY
0x4CE4 CTLPHY_WRAP__CTL_CFG__CTLCFG_DENALI_PHY_825 ro
  [25:16] PHY_RDLVL_RDDQS_DQ_TE_DLY_OBS_3 — Observation register containing read leveling data window trailing edge target delay setting for slice 3. READ-ONLY
  [9:0] PHY_RDLVL_RDDQS_DQ_LE_DLY_OBS_3 — Observation register containing read leveling data window leading edge target delay setting for slice 3. READ-ONLY
0x4CE8 CTLPHY_WRAP__CTL_CFG__CTLCFG_DENALI_PHY_826 ro
  [1:0] PHY_RDLVL_RDDQS_DQ_NUM_WINDOWS_OBS_3 — Observation register containing read leveling number of windows found for slice 3. READ-ONLY
0x4CEC CTLPHY_WRAP__CTL_CFG__CTLCFG_DENALI_PHY_827 ro
  [31:0] PHY_RDLVL_STATUS_OBS_3 — Observation register containing read leveling status for slice 3. READ-ONLY
0x4CF0 CTLPHY_WRAP__CTL_CFG__CTLCFG_DENALI_PHY_828 ro reset 0x7FF0000
  [26:16] PHY_WDQLVL_DQDM_TE_DLY_OBS_3 — Observation register containing write data leveling data window trailing edge target delay setting for slice 3. READ-ONLY
  [10:0] PHY_WDQLVL_DQDM_LE_DLY_OBS_3 — Observation register containing write data leveling data window leading edge target delay setting for slice 3. READ-ONLY
0x4CF4 CTLPHY_WRAP__CTL_CFG__CTLCFG_DENALI_PHY_829 ro
  [31:0] PHY_WDQLVL_STATUS_OBS_3 — Observation register containing write data leveling status for slice 3. READ-ONLY
0x4CF8 CTLPHY_WRAP__CTL_CFG__CTLCFG_DENALI_PHY_830 ro
  [31:0] PHY_WDQLVL_PERIODIC_OBS_3 — Observation register containing periodic write data leveling status for slice 3. READ-ONLY
0x4CFC CTLPHY_WRAP__CTL_CFG__CTLCFG_DENALI_PHY_831
  [30:0] PHY_DDL_MODE_3 — DDL mode for slice 3.
0x4D00 CTLPHY_WRAP__CTL_CFG__CTLCFG_DENALI_PHY_832
  [5:0] PHY_DDL_MASK_3 — DDL mask for slice 3.
0x4D04 CTLPHY_WRAP__CTL_CFG__CTLCFG_DENALI_PHY_833 ro
  [31:0] PHY_DDL_TEST_OBS_3 — DDL test observation for slice 3. READ-ONLY
0x4D08 CTLPHY_WRAP__CTL_CFG__CTLCFG_DENALI_PHY_834 ro
  [31:0] PHY_DDL_TEST_MSTR_DLY_OBS_3 — DDL test observation delays for slice 3 controller DDL. READ-ONLY
0x4D0C CTLPHY_WRAP__CTL_CFG__CTLCFG_DENALI_PHY_835
  [24:16] PHY_RX_CAL_DQ0_3 — RX Calibration codes for DQ0 for slice 3. Bits [5:0] contain rx_cal_code_down. Bits [11:6] contain rx_cal_code_up. Bits [17:12] contain rx_cal_code2_down. Bits [23:18] contain rx_cal_code2_up.
  [8] PHY_LP4_WDQS_OE_EXTEND_3 — LPDDR4 write preamble extension enable for slice 3.
  [7:0] PHY_DDL_TRACK_UPD_THRESHOLD_3 — Specify threshold value for PHY init update tracking for slice 3.
{0x4000+4i} CTLPHY_WRAP__CTL_CFG__CTLCFG_DENALI_PHY_{i} (i=836..838)
  [24:16] PHY_RX_CAL_DQ{2i-1670}_3 — RX Calibration codes for DQ{2i-1670} for slice 3. Bits [5:0] contain rx_cal_code_down. Bits [11:6] contain rx_cal_code_up. Bits [17:12] contain rx_cal_code2_down. Bits [23:18] contain rx_cal_code2_up.
  [8:0] PHY_RX_CAL_DQ{2i-1671}_3 — RX Calibration codes for DQ{2i-1671} for slice 3. Bits [5:0] contain rx_cal_code_down. Bits [11:6] contain rx_cal_code_up. Bits [17:12] contain rx_cal_code2_down. Bits [23:18] contain rx_cal_code2_up.
0x4D1C CTLPHY_WRAP__CTL_CFG__CTLCFG_DENALI_PHY_839
  [8:0] PHY_RX_CAL_DQ7_3 — RX Calibration codes for DQ7 for slice 3. Bits [5:0] contain rx_cal_code_down. Bits [11:6] contain rx_cal_code_up. Bits [17:12] contain rx_cal_code2_down. Bits [23:18] contain rx_cal_code2_up.
0x4D20 CTLPHY_WRAP__CTL_CFG__CTLCFG_DENALI_PHY_840
  [17:0] PHY_RX_CAL_DM_3 — RX Calibration codes for DM for slice 3. Bits [5:0] contain rx_cal_code_down. Bits [11:6] contain rx_cal_code_up. Bits [17:12] contain rx_cal_code2_down. Bits [23:18] contain rx_cal_code2_up.
0x4D24 CTLPHY_WRAP__CTL_CFG__CTLCFG_DENALI_PHY_841
  [24:16] PHY_RX_CAL_FDBK_3 — RX Calibration codes for FDBK for slice 3. Bits [5:0] contain rx_cal_code_down. Bits [11:6] contain rx_cal_code_up. Bits [17:12] contain rx_cal_code2_down. Bits [23:18] contain rx_cal_code2_up.
  [8:0] PHY_RX_CAL_DQS_3 — RX Calibration codes for DQS for slice 3. Bits [5:0] contain rx_cal_code_down. Bits [11:6] contain rx_cal_code_up. Bits [17:12] contain rx_cal_code2_down. Bits [23:18] contain rx_cal_code2_up.
0x4D28 CTLPHY_WRAP__CTL_CFG__CTLCFG_DENALI_PHY_842
  [31:24] PHY_DATA_DC_CAL_SAMPLE_WAIT_3 — Determines number of cycles to wait for each sample for slice 3.
  [20:16] PHY_STATIC_TOG_DISABLE_3 — Control to disable toggle during static activity for slice 3. bit0: Write path delay line disable; bit1: Read path delay line disable; bit2: Read data path disable; bit3: clk_phy disable; bit4: controller delay line disable.
  [10:0] PHY_PAD_RX_BIAS_EN_3 — Controls RX_BIAS_EN pin for each pad for slice 3.
0x4D2C CTLPHY_WRAP__CTL_CFG__CTLCFG_DENALI_PHY_843
  [31:24] PHY_DATA_DC_ADJUST_SAMPLE_CNT_3 — Duty cycle adjust sample count for slice 3.
  [21:16] PHY_DATA_DC_ADJUST_START_3 — Duty cycle adjust starting value for slice 3.
  [9:8] PHY_DATA_DC_WEIGHT_3 — Determines weight of average calculating for slice 3.
  [7:0] PHY_DATA_DC_CAL_TIMEOUT_3 — Determines timeout number of iteration for slice 3.
0x4D30 CTLPHY_WRAP__CTL_CFG__CTLCFG_DENALI_PHY_844
  [24] PHY_DATA_DC_CAL_START_3 — Manual trigger for DCC for slice 3.
  [16] PHY_DATA_DC_CAL_POLARITY_3 — Calibration polarity for slice 3.
  [8] PHY_DATA_DC_ADJUST_DIRECT_3 — Adjust direction for slice 3.
  [7:0] PHY_DATA_DC_ADJUST_THRSHLD_3 — Duty cycle adjust threshold around the mid-point for slice 3.
0x4D34 CTLPHY_WRAP__CTL_CFG__CTLCFG_DENALI_PHY_845 reset 0x1
  [24] PHY_RDPATH_GATE_DISABLE_3 — Data slice read path power reduction disable for slice 3.
  [16] PHY_SLV_DLY_CTRL_GATE_DISABLE_3 — Data slice slv_dly_control block power reduction disable for slice 3.
  [10:8] PHY_FDBK_PWR_CTRL_3 — Shutoff gate feedback IO to reduce power for slice 3.
  [1:0] PHY_DATA_DC_SW_RANK_3 — Rank selection for software based duty cycle correction for slice 3.
0x4D38 CTLPHY_WRAP__CTL_CFG__CTLCFG_DENALI_PHY_846
  [8] PHY_SLICE_PWR_RDC_DISABLE_3 — Data slice power reduction disable for slice 3.
  [0] PHY_DCC_RXCAL_CTRL_GATE_DISABLE_3 — Data slice DCC and RX_CAL block power reduction disable for slice 3.
0x4D3C CTLPHY_WRAP__CTL_CFG__CTLCFG_DENALI_PHY_847
  [26:24] PHY_DQS_TSEL_ENABLE_3 — Operation type tsel enables for DQS signals for slice 3. Bit [0] enables tsel_en during read cycles. Bit [1] enables tsel_en during write cycles. Bit [2] enables tsel_en during idle cycles. Set each bit to 1 to enable.
  [23:8] PHY_DQ_TSEL_SELECT_3 — Operation type tsel select values for DQ/DM signals for slice 3.
  [2:0] PHY_DQ_TSEL_ENABLE_3 — Operation type tsel enables for DQ/DM signals for slice 3. Bit [0] enables tsel_en during read cycles. Bit [1] enables tsel_en during write cycles. Bit [2] enables tsel_en during idle cycles. Set each bit to 1 to enable.
0x4D40 CTLPHY_WRAP__CTL_CFG__CTLCFG_DENALI_PHY_848
  [30:24] PHY_VREF_INITIAL_START_POINT_3 — Data slice initial VREF training start value for slice 3.
  [17:16] PHY_TWO_CYC_PREAMBLE_3 — 2 cycle preamble support for slice 3. Bit [0] controls the 2 cycle read preamble. Bit [1] controls the 2 cycle write preamble. Set each bit to 1 to enable.
  [15:0] PHY_DQS_TSEL_SELECT_3 — Operation type tsel select values for DQS signals for slice 3.
0x4D44 CTLPHY_WRAP__CTL_CFG__CTLCFG_DENALI_PHY_849
  [31:24] PHY_NTP_WDQ_STEP_SIZE_3 — Step size of WR DQ target delay during No-Topology training for slice 3.
  [16] PHY_NTP_TRAIN_EN_3 — Enable for No-Topology training for slice 3.
  [9:8] PHY_VREF_TRAINING_CTRL_3 — Data slice vref training enable control for slice 3.
  [6:0] PHY_VREF_INITIAL_STOP_POINT_3 — Data slice initial VREF training stop value for slice 3.
0x4D48 CTLPHY_WRAP__CTL_CFG__CTLCFG_DENALI_PHY_850
  [26:16] PHY_NTP_WDQ_STOP_3 — End of WR DQ target delay in No-Topology training for slice 3.
  [10:0] PHY_NTP_WDQ_START_3 — Starting WR DQ target delay in No-Topology training for slice 3.
0x4D4C CTLPHY_WRAP__CTL_CFG__CTLCFG_DENALI_PHY_851
  [24] PHY_SW_WDQLVL_DVW_MIN_EN_3 — SW override to enable use of PHY_WDQLVL_DVW_MIN for slice 3.
  [17:8] PHY_WDQLVL_DVW_MIN_3 — Minimum data valid window across DQs and ranks for slice 3.
  [7:0] PHY_NTP_WDQ_BIT_EN_3 — Enable Bit for WR DQ during No-Topology training for slice 3.
0x4D50 CTLPHY_WRAP__CTL_CFG__CTLCFG_DENALI_PHY_852
  [28:24] PHY_PAD_RX_DCD_0_3 — Controls RX_DCD pin for each pad for slice 3.
  [20:16] PHY_PAD_TX_DCD_3 — Controls TX_DCD pin for each pad for slice 3.
  [11:8] PHY_FAST_LVL_EN_3 — Enable for fast multi-pattern window search for slice 3.
  [5:0] PHY_WDQLVL_PER_START_OFFSET_3 — Peridic training start point offset for slice 3.
0x4D54 CTLPHY_WRAP__CTL_CFG__CTLCFG_DENALI_PHY_853
  [8n-4:8n-8] PHY_PAD_RX_DCD_{n}_3 (n=1..4) — Controls RX_DCD pin for each pad for slice 3.
0x4D58 CTLPHY_WRAP__CTL_CFG__CTLCFG_DENALI_PHY_854
  [28:24] PHY_PAD_DM_RX_DCD_3 — Controls RX_DCD pin for dm pad for slice 3.
  [20:16] PHY_PAD_RX_DCD_7_3 — Controls RX_DCD pin for each pad for slice 3.
  [12:8] PHY_PAD_RX_DCD_6_3 — Controls RX_DCD pin for each pad for slice 3.
  [4:0] PHY_PAD_RX_DCD_5_3 — Controls RX_DCD pin for each pad for slice 3.
0x4D5C CTLPHY_WRAP__CTL_CFG__CTLCFG_DENALI_PHY_855
  [22:16] PHY_PAD_DSLICE_IO_CFG_3 — Controls PCLK/PARK pin for pad for slice 3.
  [12:8] PHY_PAD_FDBK_RX_DCD_3 — Controls RX_DCD pin for fdbk pad for slice 3.
  [4:0] PHY_PAD_DQS_RX_DCD_3 — Controls RX_DCD pin for dqs pad for slice 3.
{0x4000+4i} CTLPHY_WRAP__CTL_CFG__CTLCFG_DENALI_PHY_{i} (i=856..859)
  [25:16] PHY_RDDQ{2i-1711}_SLAVE_DELAY_3 — Read DQ{2i-1711} target delay setting for slice 3.
  [9:0] PHY_RDDQ{2i-1712}_SLAVE_DELAY_3 — Read DQ{2i-1712} target delay setting for slice 3.
0x4D70 CTLPHY_WRAP__CTL_CFG__CTLCFG_DENALI_PHY_860
  [28:24] PHY_RX_CAL_ALL_DLY_3 — Defines the number of cycles/half cycles that the rx_cal_all_opad signal should be asserted for. There is a phy_rx_cal_all_dly_X parameter for each of the slices of data sent on the DFI data bus for slice 3.
  [18:16] PHY_RX_PCLK_CLK_SEL_3 — RX_PCLK clock frequency selection for slice 3.
  [9:0] PHY_RDDM_SLAVE_DELAY_3 — Read DM/DBI target delay setting for slice 3. May be used for data swap.
0x4D74 CTLPHY_WRAP__CTL_CFG__CTLCFG_DENALI_PHY_861
  [2:0] PHY_DATA_DC_CAL_CLK_SEL_3 — Determines DCC CAL clock for slice 3.
0x4D78 CTLPHY_WRAP__CTL_CFG__CTLCFG_DENALI_PHY_862
  [31:24] PHY_DQS_OE_TIMING_3 — Start/end timing values for DQS output enable signals for slice 3.
  [23:16] PHY_DQ_TSEL_WR_TIMING_3 — Start/end timing values for DQ/DM write based termination enable and select signals for slice 3.
  [15:8] PHY_DQ_TSEL_RD_TIMING_3 — Start/end timing values for DQ/DM read based termination enable and select signals for slice 3.
  [7:0] PHY_DQ_OE_TIMING_3 — Start/end timing values for DQ/DM output enable signals for slice 3.
0x4D7C CTLPHY_WRAP__CTL_CFG__CTLCFG_DENALI_PHY_863
  [31:24] PHY_DQS_TSEL_WR_TIMING_3 — Start/end timing values for DQS write based termination enable and select signals for slice 3.
  [23:16] PHY_DQS_OE_RD_TIMING_3 — Start/end timing values for DQS read based OE extension for slice 3.
  [15:8] PHY_DQS_TSEL_RD_TIMING_3 — Start/end timing values for DQS read based termination enable and select signals for slice 3.
  [3:0] PHY_IO_PAD_DELAY_TIMING_3 — Feedback pad's OPAD and IPAD delay timing for slice 3.
0x4D80 CTLPHY_WRAP__CTL_CFG__CTLCFG_DENALI_PHY_864
  [27:16] PHY_PAD_VREF_CTRL_DQ_3 — Pad VREF control settings for DQ slice 3.
  [15:0] PHY_VREF_SETTING_TIME_3 — Number of cycles for vref settle after setting is changed for slice 3.
0x4D84 CTLPHY_WRAP__CTL_CFG__CTLCFG_DENALI_PHY_865
  [25:24] PHY_RDDATA_EN_IE_DLY_3 — Number of cycles that the dfi_rddata_en signal is earlier than necessary for input enable generation for slice 3.
  [23:16] PHY_DQS_IE_TIMING_3 — Start/end timing values for DQS input enable signals for slice 3.
  [15:8] PHY_DQ_IE_TIMING_3 — Start/end timing values for DQ/DM input enable signals for slice 3.
  [0] PHY_PER_CS_TRAINING_EN_3 — Enables the per-rank training and read/write timing capabilities for slice 3. Must have same value in all slices.
0x4D88 CTLPHY_WRAP__CTL_CFG__CTLCFG_DENALI_PHY_866
  [28:24] PHY_WDQLVL_RDDATA_EN_DLY_3 — For WR DQ training, the number of cycles that the dfi_rddata_en signal is early for slice 3.
  [16] PHY_WDQLVL_IE_ON_3 — IE control, 1 meams IE is always on during WR DQ training for slice 3.
  [9:8] PHY_DBI_MODE_3 — DBI mode for slice 3. Bit [0] enables return of DBI read data.
  [1:0] PHY_IE_MODE_3 — Input enable mode bits for slice 3. Bit [0] enables the mode where the input enables are always on; set to 1 to enable. Bit [1] disables the input enable on the DM signal; set to 1 to disable.
0x4D8C CTLPHY_WRAP__CTL_CFG__CTLCFG_DENALI_PHY_867
  [27:24] PHY_SW_MASTER_MODE_3 — Controller delay line override settings for slice 3. Bit [0] enables software half clock mode. Bit [1] is the software half clock mode value. Bit [2] enables software bypass mode. Bit [3] is the software bypass mode value.
  [20:16] PHY_RDDATA_EN_OE_DLY_3 — Number of cycles that the dfi_rddata_en signal is earlier than necessary for LP4 OE extension generation for slice 3.
  [12:8] PHY_RDDATA_EN_TSEL_DLY_3 — Number of cycles that the dfi_rddata_en signal is earlier than necessary for TSEL enable generation for slice 3.
  [4:0] PHY_WDQLVL_RDDATA_EN_TSEL_DLY_3 — For WR DQ training, the number of cycles that the dfi_rddata_en signal is earlier than necessary for TSEL enable generation for slice 3.
0x4D90 CTLPHY_WRAP__CTL_CFG__CTLCFG_DENALI_PHY_868
  [31:24] PHY_MASTER_DELAY_WAIT_3 — Wait cycles for controller delay line locking algorithm for slice 3. Bits [3:0] are the cycle wait count after a calibration clock setting change. Bits [7:4] are the cycle wait count after a controller delay setting change.
  [21:16] PHY_MASTER_DELAY_STEP_3 — Incremental step size for controller delay line locking algorithm for slice 3.
  [10:0] PHY_MASTER_DELAY_START_3 — Start value for controller delay line locking algorithm for slice 3.
0x4D94 CTLPHY_WRAP__CTL_CFG__CTLCFG_DENALI_PHY_869
  [27:24] PHY_WRLVL_DLY_FINE_STEP_3 — DQS target delay fine step size during write leveling for slice 3.
  [23:16] PHY_WRLVL_DLY_STEP_3 — DQS target delay step size during write leveling for slice 3.
  [11:8] PHY_RPTR_UPDATE_3 — Offset in cycles from the dfi_rddata_en signal to release data from the entry FIFO for slice 3.
  [7:0] PHY_MASTER_DELAY_HALF_MEASURE_3 — Defines the number of delay line elements to be considered in determing whether to lock to a half clock cycle in the data slice controller for slice 3.
